# DA1469x register map
Vendor: Dialog; Series: DA1469x; File version: 1.2
CPU: CM33 r1p0, little endian, no MPU, FPU, 3 interrupt priority bits
Registers are 32-bit, read-write, reset 0x0 unless marked. A register's access mark holds for its fields unless they carry their own. Offsets are from the block's base; [hi:lo] are bit positions.

## RFMON — RFMON registers
Base 0x50040600
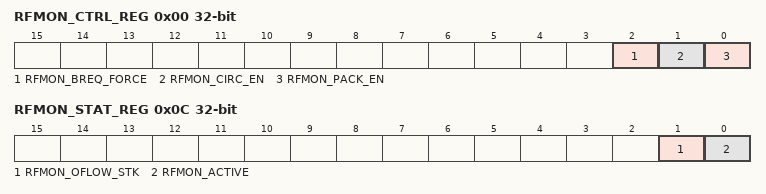
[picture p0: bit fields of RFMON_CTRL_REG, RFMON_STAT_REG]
0x00 RFMON_CTRL_REG — Control register
  [2] RFMON_BREQ_FORCE — Write this bit with 1, when the required throughput for the transferring of the captured data is close to the capacity of the system bus/memory. The controller will be aggressive in the usage of the bus. The availability of the bus will be affected for the remaining masters.
  [1] RFMON_CIRC_EN — Write with 1 to enable the circular mode. In circular mode the controller continuously writes data in to the memory until being disabled by software. Data are transferred in the circular buffer in the memory, as defined by RFMON_ADDR_REG and RFMON_LEN_REG registers. Disabling of the controller is realized by writing RFMON_PACK_EN with 0.
  [0] RFMON_PACK_EN — Starts capturing data from the test bus 0 : No data captured. 1 : Data captured. Should be written with 1 to start data acquisition. When the controller is not in circular mode (RFMON_CIRC_EN = 0) and after capturing a predefined number of words (RFMON_LEN), this bit will be auto cleared. In circular mode (RFMON_CIRC_EN = 1) the RFMON_PACK_EN remains 1 to be cleared by software.
0x04 RFMON_ADDR_REG (reset mask 0x7FFFFFFF) — AHB master start address
  [31:2] RFMON_ADDR — It is the bits [31:2] of base address that is used by the AHB master interface of the controller. Defines the AHB address where the controller will start storing data at. Bits [1:0] of the address are always considered to be 0.
0x08 RFMON_LEN_REG — Data length register
  [16:0] RFMON_LEN — The number of words (minus one) that should be captured.
0x0C RFMON_STAT_REG — Status register
  [1] RFMON_OFLOW_STK — Indicates that during transfer of data, at least one overflow has been detected. 0 : The transfer completed without overflows. 1 : At least one overflow occured in the fifo. Write 1 to clear this bit.
  [0] RFMON_ACTIVE ro — Indicates the state of the controller. 0 : The controller is idle. 1 : The controller is active. The capturing process and/or the dma activity is in progress. The controller will be activated (RFMON_ACTIVE == 1), when RFMON_PACK_EN will be written with 1. Will return to inactive state, after the end of the capturing process (RFMON_PACK_EN==0) and the completion of the transfer of all data to memory.
0x10 RFMON_CRV_ADDR_REG (reset mask 0x7FFFFFFF) — AHB master current address
  [31:2] RFMON_CRV_ADDR ro — Bits [31:2] of AHB address that will be used by the controller in the next memory access. The bits [1:0] are always 0.
0x14 RFMON_CRV_LEN_REG — The remaining data to be transferred
  [16:0] RFMON_CRV_LEN ro — Indicates the number of words (minus 1) that remain to be transfered.

## SDADC — SDADC registers
Base 0x50020800
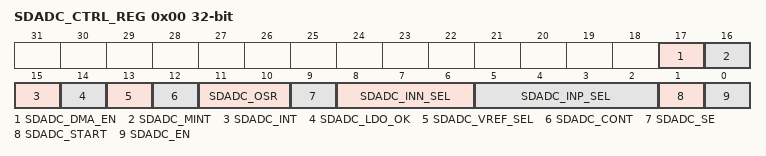
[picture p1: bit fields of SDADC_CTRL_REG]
0x00 SDADC_CTRL_REG — Sigma Delta ADC Control Register
  [17] SDADC_DMA_EN — 0: DMA functionality disabled 1: DMA functionality enabled
  [16] SDADC_MINT — 0: Disable (mask) SDADC_ADC_INT. 1: Enable SDADC_ADC_INT to ICU.
  [15] SDADC_INT ro — 1: AD conversion ready and has generated an interrupt. Must be cleared by writing any value to SDADC_CLEAR_INT_REG.
  [14] SDADC_LDO_OK ro — 1: Internal LDO is ready for use
  [13] SDADC_VREF_SEL — 0: Internal bandgap reference. 1: External reference.
  [12] SDADC_CONT — 0: Manual ADC mode, a single result will be generated after setting the SDADC_START bit. 1: Continuous ADC mode, new ADC results will be constantly stored in SDADC_RESULT_REG. Still SDADC_START has to be set to start the execution. Wait for SDADC_START to become zero after clearing the SDADC_CONT bit to stop the continuous mode.
  [11:10] SDADC_OSR — Oversample Rate 0: 128x 1: 256x 2: 512x 3: 1024x
  [9] SDADC_SE — 0: Differential mode 1: Single ended mode (Input selection negative side is ignored)
  [8:6] SDADC_INN_SEL — Input selection of negative side. 0: ADC0 / P1[09] 1: ADC1 / P0[25] 2: ADC2 / P0[08] 3: ADC3 / P0[09] 4: ADC4 / P1[14] 5: ADC5 / P1[20] 6: ADC6 / P1[21] 7: ADC7 / P1[22]
  [5:2] SDADC_INP_SEL — Input selection of positive side. 0: ADC0 / P1[09] 1: ADC1 / P0[25] 2: ADC2 / P0[08] 3: ADC3 / P0[09] 4: ADC4 / P1[14] 5: ADC5 / P1[20] 6: ADC6 / P1[21] 7: ADC7 / P1[22] 8: VBAT (via 4x attenuator, INN connected to ground)
  [1] SDADC_START — 0: ADC conversion ready. 1: If a 1 is written, the ADC starts a conversion. After the conversion this bit will be set to 0 and the SDADC_INT bit will be set. It is not allowed to write this bit while it is not (yet) zero.
  [0] SDADC_EN — 0: LDO is off and ADC is disabled. 1: LDO, bias currents and modulator are enabled.
0x0C SDADC_GAIN_CORR_REG — Sigma Delta ADC Gain Correction Register
  [9:0] SDADC_GAIN_CORR — Gain adjust
0x10 SDADC_OFFS_CORR_REG — Sigma Delta ADC Offset Correction Register
  [9:0] SDADC_OFFS_CORR — Offset adjust
0x14 SDADC_CLEAR_INT_REG — Sigma Delta ADC Clear Interrupt Register
  [15:0] SDADC_CLR_INT wo — Writing any value to this register will clear the ADC_INT interrupt. Reading returns 0.
0x18 SDADC_RESULT_REG — Sigma Delta ADC Result Register
  [15:0] SDADC_VAL ro — Returns up to 16 bits linear value of the last AD conversion. The effective resolution depends on the OSR used.
